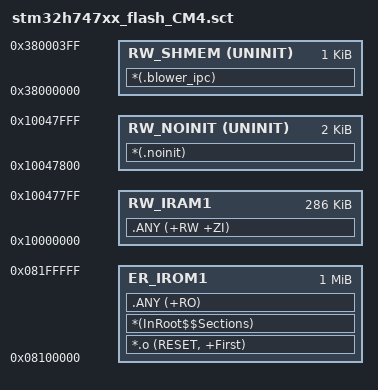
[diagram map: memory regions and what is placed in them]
; *************************************************************
; *** Scatter-Loading Description File generated by uVision ***
; *************************************************************

LR_IROM1 0x08100000 0x00100000  {    ; load region size_region
  ER_IROM1 0x08100000 0x00100000  {  ; load address = execution address
   *.o (RESET, +First)
   *(InRoot$$Sections)
   .ANY (+RO)
  }
  RW_NOINIT 0x10047800 UNINIT 0x00000800  {
   *(.noinit)
  }
  RW_SHMEM 0x38000000 UNINIT 0x00000400  {
   *(.blower_ipc)
  }
  RW_IRAM1 0x10000000 0x00047800  {
   .ANY (+RW +ZI)
  }
}
